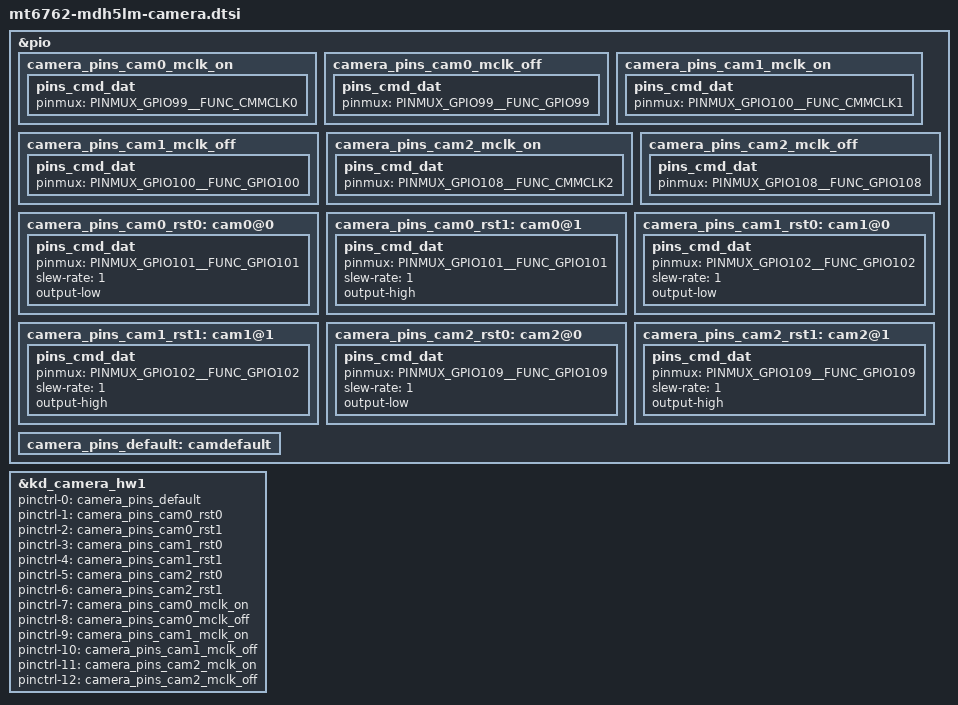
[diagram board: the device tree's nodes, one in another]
/*
 * Copyright (c) 2019 MediaTek Inc.
 *
 * This program is free software; you can redistribute it and/or modify
 * it under the terms of the GNU General Public License version 2 as
 * published by the Free Software Foundation.
 *
 * This program is distributed in the hope that it will be useful,
 * but WITHOUT ANY WARRANTY; without even the implied warranty of
 * MERCHANTABILITY or FITNESS FOR A PARTICULAR PURPOSE.  See the
 * GNU General Public License for more details.
 */
/* CAMERA GPIO standardization */
&pio {
	camera_pins_cam0_mclk_on: camera_pins_cam0_mclk_on {
		pins_cmd_dat {
			pinmux = <PINMUX_GPIO99__FUNC_CMMCLK0>;
		};
	};
	camera_pins_cam0_mclk_off: camera_pins_cam0_mclk_off {
		pins_cmd_dat {
			pinmux = <PINMUX_GPIO99__FUNC_GPIO99>;
		};
	};
	camera_pins_cam1_mclk_on: camera_pins_cam1_mclk_on {
		pins_cmd_dat {
			pinmux = <PINMUX_GPIO100__FUNC_CMMCLK1>;
		};
	};
	camera_pins_cam1_mclk_off: camera_pins_cam1_mclk_off {
		pins_cmd_dat {
			pinmux = <PINMUX_GPIO100__FUNC_GPIO100>;
		};
	};
	camera_pins_cam2_mclk_on: camera_pins_cam2_mclk_on {
		pins_cmd_dat {
			pinmux = <PINMUX_GPIO108__FUNC_CMMCLK2>;
		};
	};
	camera_pins_cam2_mclk_off: camera_pins_cam2_mclk_off {
		pins_cmd_dat {
			pinmux = <PINMUX_GPIO108__FUNC_GPIO108>;
		};
	};
	camera_pins_cam0_rst0: cam0@0 {
		pins_cmd_dat {
			pinmux = <PINMUX_GPIO101__FUNC_GPIO101>;
			slew-rate = <1>;
			output-low;
		};
	};
	camera_pins_cam0_rst1: cam0@1 {
		pins_cmd_dat {
			pinmux = <PINMUX_GPIO101__FUNC_GPIO101>;
			slew-rate = <1>;
			output-high;
		};
	};
	camera_pins_cam1_rst0: cam1@0 {
		pins_cmd_dat {
			pinmux = <PINMUX_GPIO102__FUNC_GPIO102>;
			slew-rate = <1>;
			output-low;
		};
	};
	camera_pins_cam1_rst1: cam1@1 {
		pins_cmd_dat {
			pinmux = <PINMUX_GPIO102__FUNC_GPIO102>;
			slew-rate = <1>;
			output-high;
		};
	};
	camera_pins_cam2_rst0: cam2@0 {
		pins_cmd_dat {
			pinmux = <PINMUX_GPIO109__FUNC_GPIO109>;
			slew-rate = <1>;
			output-low;
		};
	};
	camera_pins_cam2_rst1: cam2@1 {
		pins_cmd_dat {
			pinmux = <PINMUX_GPIO109__FUNC_GPIO109>;
			slew-rate = <1>;
			output-high;
		};
	};
	camera_pins_default: camdefault {
	};

};

&kd_camera_hw1 {
	pinctrl-names = "default",
			"cam0_rst0",
			"cam0_rst1",
			"cam1_rst0",
			"cam1_rst1",
			"cam2_rst0",
			"cam2_rst1",
			"cam0_mclk_on",
			"cam0_mclk_off",
			"cam1_mclk_on",
			"cam1_mclk_off",
			"cam2_mclk_on",
			"cam2_mclk_off";

	pinctrl-0 = <&camera_pins_default>;
	pinctrl-1 = <&camera_pins_cam0_rst0>;
	pinctrl-2 = <&camera_pins_cam0_rst1>;
	pinctrl-3 = <&camera_pins_cam1_rst0>;
	pinctrl-4 = <&camera_pins_cam1_rst1>;
	pinctrl-5 = <&camera_pins_cam2_rst0>;
	pinctrl-6 = <&camera_pins_cam2_rst1>;
	pinctrl-7 = <&camera_pins_cam0_mclk_on>;
	pinctrl-8 = <&camera_pins_cam0_mclk_off>;
	pinctrl-9 = <&camera_pins_cam1_mclk_on>;
	pinctrl-10 = <&camera_pins_cam1_mclk_off>;
	pinctrl-11 = <&camera_pins_cam2_mclk_on>;
	pinctrl-12 = <&camera_pins_cam2_mclk_off>;

	status = "okay";

};
/* CAMERA GPIO end */
